# ESP32-S31 register map
Vendor: ESPRESSIF SYSTEMS (SHANGHAI) CO., LTD.; Series: ESP32 S-Series; File version: 1
CPU: RV32IMAFC r0p0, little endian, no MPU, FPU, 0 interrupt priority bits
Address unit: 32 bits
Registers are 32-bit, read-write, reset 0x0 unless marked. A register's access mark holds for its fields unless they carry their own. Offsets are from the block's base; [hi:lo] are bit positions; {n}, {i} and the like mark numbered series.

## ZERO_DET — ZERO_DET Peripheral
Base 0x2039A000
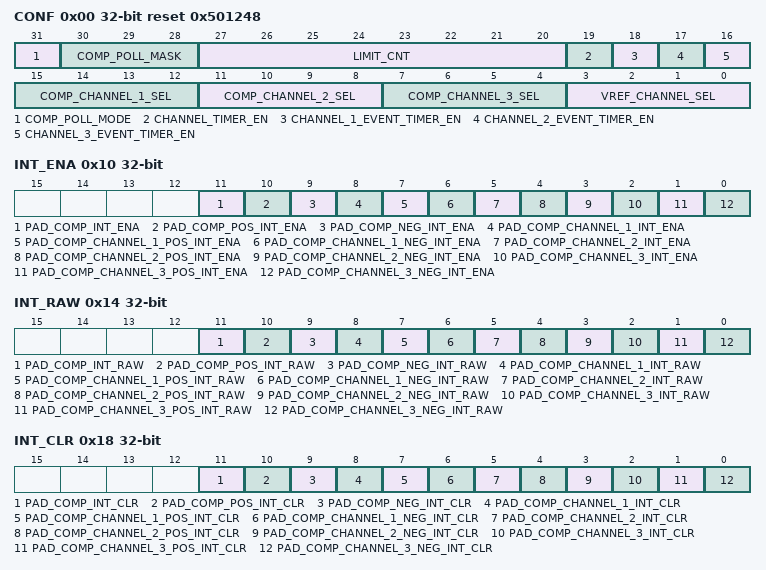
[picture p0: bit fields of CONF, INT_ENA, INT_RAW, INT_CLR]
0x00 CONF reset 0x501248 — zero det cfg reg
  [31] COMP_POLL_MODE — cfg channel scan mode ,0 means one trigger scan all mask channel, 1 means one trigger scan one mask channel
  [30:28] COMP_POLL_MASK — mask channel to do pad compare and zero det
  [27:20] LIMIT_CNT — cfg continuous zero det num to change zero det result
  [19] CHANNEL_TIMER_EN — enable timer to record the time between two continuous zero det int in each channel
  [18] CHANNEL_1_EVENT_TIMER_EN — enable channel 1 event timer to trigger channel 1 event after pad_comp_channel_1_int
  [17] CHANNEL_2_EVENT_TIMER_EN — enable channel 2 event timer to trigger channel 1 event after pad_comp_channel_2_int
  [16] CHANNEL_3_EVENT_TIMER_EN — enable channel 3 event timer to trigger channel 1 event after pad_comp_channel_3_int
  [15:12] COMP_CHANNEL_1_SEL — Channel 1 comp pad sel,one hot code and cannot set the same bit with other channels
  [11:8] COMP_CHANNEL_2_SEL — Channel 2 comp pad sel,one hot code and cannot set the same bit with other channels
  [7:4] COMP_CHANNEL_3_SEL — Channel 3 comp pad sel,one hot code and cannot set the same bit with other channels
  [3:0] VREF_CHANNEL_SEL — vref pad sel,one hot code and cannot set the same bit with other channels
0x04 FILTER_CNT reset 0xFF — protect time reg
  [31:0] FILTER_CNT — protect time after det the frist zero det int,it must be greater than or equal to 1
0x08 POLL_PERIOD reset 0xF — poll period time reg
  [15:0] COMP_POLL_PERIOD — poll period time for each cahnnel,it must be greater than or equal to 1
0x0C DELAY_EVENT_TIME reset 0xF — delay time reg
  [15:0] DELAY_EVENT_TIME — delay time after zero det int to trigger event for each channel ,it must be greater than or equal to 1
0x10 INT_ENA — zero det int ena
  [11] PAD_COMP_INT_ENA — reserved
  [10] PAD_COMP_POS_INT_ENA — reserved
  [9] PAD_COMP_NEG_INT_ENA — reserved
  [8] PAD_COMP_CHANNEL_1_INT_ENA — reserved
  [7] PAD_COMP_CHANNEL_1_POS_INT_ENA — reserved
  [6] PAD_COMP_CHANNEL_1_NEG_INT_ENA — reserved
  [5] PAD_COMP_CHANNEL_2_INT_ENA — reserved
  [4] PAD_COMP_CHANNEL_2_POS_INT_ENA — reserved
  [3] PAD_COMP_CHANNEL_2_NEG_INT_ENA — reserved
  [2] PAD_COMP_CHANNEL_3_INT_ENA — reserved
  [1] PAD_COMP_CHANNEL_3_POS_INT_ENA — reserved
  [0] PAD_COMP_CHANNEL_3_NEG_INT_ENA — reserved
0x14 INT_RAW — zero det int raw
  [11] PAD_COMP_INT_RAW — reserved
  [10] PAD_COMP_POS_INT_RAW — reserved
  [9] PAD_COMP_NEG_INT_RAW — reserved
  [8] PAD_COMP_CHANNEL_1_INT_RAW — reserved
  [7] PAD_COMP_CHANNEL_1_POS_INT_RAW — reserved
  [6] PAD_COMP_CHANNEL_1_NEG_INT_RAW — reserved
  [5] PAD_COMP_CHANNEL_2_INT_RAW — reserved
  [4] PAD_COMP_CHANNEL_2_POS_INT_RAW — reserved
  [3] PAD_COMP_CHANNEL_2_NEG_INT_RAW — reserved
  [2] PAD_COMP_CHANNEL_3_INT_RAW — reserved
  [1] PAD_COMP_CHANNEL_3_POS_INT_RAW — reserved
  [0] PAD_COMP_CHANNEL_3_NEG_INT_RAW — reserved
0x18 INT_CLR wo — zero det int clr
  [11] PAD_COMP_INT_CLR — reserved
  [10] PAD_COMP_POS_INT_CLR — reserved
  [9] PAD_COMP_NEG_INT_CLR — reserved
  [8] PAD_COMP_CHANNEL_1_INT_CLR — reserved
  [7] PAD_COMP_CHANNEL_1_POS_INT_CLR — reserved
  [6] PAD_COMP_CHANNEL_1_NEG_INT_CLR — reserved
  [5] PAD_COMP_CHANNEL_2_INT_CLR — reserved
  [4] PAD_COMP_CHANNEL_2_POS_INT_CLR — reserved
  [3] PAD_COMP_CHANNEL_2_NEG_INT_CLR — reserved
  [2] PAD_COMP_CHANNEL_3_INT_CLR — reserved
  [1] PAD_COMP_CHANNEL_3_POS_INT_CLR — reserved
  [0] PAD_COMP_CHANNEL_3_NEG_INT_CLR — reserved
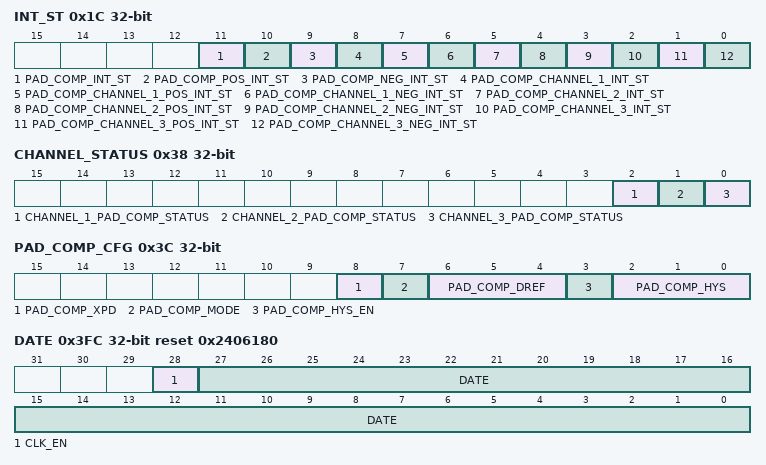
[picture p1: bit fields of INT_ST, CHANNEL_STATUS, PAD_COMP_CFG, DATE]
0x1C INT_ST ro — zero det int st
  [11] PAD_COMP_INT_ST — reserved
  [10] PAD_COMP_POS_INT_ST — reserved
  [9] PAD_COMP_NEG_INT_ST — reserved
  [8] PAD_COMP_CHANNEL_1_INT_ST — reserved
  [7] PAD_COMP_CHANNEL_1_POS_INT_ST — reserved
  [6] PAD_COMP_CHANNEL_1_NEG_INT_ST — reserved
  [5] PAD_COMP_CHANNEL_2_INT_ST — reserved
  [4] PAD_COMP_CHANNEL_2_POS_INT_ST — reserved
  [3] PAD_COMP_CHANNEL_2_NEG_INT_ST — reserved
  [2] PAD_COMP_CHANNEL_3_INT_ST — reserved
  [1] PAD_COMP_CHANNEL_3_POS_INT_ST — reserved
  [0] PAD_COMP_CHANNEL_3_NEG_INT_ST — reserved
{0x18+8i} CHANNEL_{i}_TIMER0 ro (i=1..3) — record timer reg
  [31:0] CHANNEL_{i}_TIMER0 — record the time while detect the frist zero det int in channel {i}
{0x1C+8i} CHANNEL_{i}_TIMER1 ro (i=1..3) — record timer reg
  [31:0] CHANNEL_{i}_TIMER1 — record the time while detect the second zero det int in channel {i}
0x38 CHANNEL_STATUS ro — pad comp status reg
  [2] CHANNEL_1_PAD_COMP_STATUS — record the pad comp status for channel 1, 0 means now is neg int , 1 means now is pos int
  [1] CHANNEL_2_PAD_COMP_STATUS — record the pad comp status for channel 2, 0 means now is neg int , 1 means now is pos int
  [0] CHANNEL_3_PAD_COMP_STATUS — record the pad comp status for channel 3, 0 means now is neg int , 1 means now is pos int
0x3C PAD_COMP_CFG — pad comp cfg reg
  [8] PAD_COMP_XPD
  [7] PAD_COMP_MODE — pad comp mode cfg 1:external pad 0:internal vref
  [6:4] PAD_COMP_DREF — internal vref cfg singal,0~2.3v step is 330mv
  [3] PAD_COMP_HYS_EN — enable hys function,only works while pad comp mode = 0
  [2:0] PAD_COMP_HYS — hys cfg singal
0x40 START wo — zero det start configure register
  [0] COMP_START — enable comp task by software
0x3FC DATE reset 0x2406180 — zero det reg change date
  [28] CLK_EN — reg clk en
  [27:0] DATE — zero det reg change date
